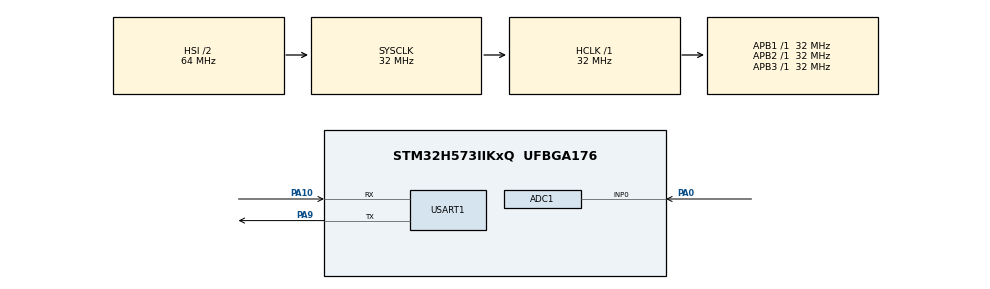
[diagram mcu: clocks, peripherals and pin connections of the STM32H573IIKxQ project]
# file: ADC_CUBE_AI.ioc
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ADC1.Channel-0\#ChannelRegularConversion=ADC_CHANNEL_0
ADC1.MonitoredBy-0\#ChannelRegularConversion=__NULL
ADC1.NbrOfConversionFlag=1
ADC1.OffsetNumber-0\#ChannelRegularConversion=ADC_OFFSET_NONE
ADC1.Rank-0\#ChannelRegularConversion=1
ADC1.SamplingTime-0\#ChannelRegularConversion=ADC_SAMPLETIME_2CYCLES_5
ADC1.master=1
BOOTPATH.BootPathName=LEGACY
BOOTPATH.UserSelectedBootPath=LEGACY
CORTEX_M33_NS.userName=CORTEX_M33
Mcu.Family=STM32H5
Mcu.Name=STM32H573IIKxQ
Mcu.Package=UFBGA176
NVIC.PriorityGroup=NVIC_PRIORITYGROUP_4
PA0.Signal=ADCx_INP0
PA10.Mode=Asynchronous
PA10.Signal=USART1_RX
PA9.Mode=Asynchronous
PA9.Signal=USART1_TX
PH0-OSC_IN(PH0).Mode=HSE-DIG-External-Clock-Source
PH0-OSC_IN(PH0).Signal=RCC_OSC_IN
ProjectManager.HeapSize=0x800
ProjectManager.StackSize=0x800
ProjectManager.TargetToolchain=STM32CubeIDE
RCC.ADCFreq_Value=32000000
RCC.AHBFreq_Value=32000000
RCC.APB1Freq_Value=32000000
RCC.APB1TimFreq_Value=32000000
RCC.APB2Freq_Value=32000000
RCC.APB2TimFreq_Value=32000000
RCC.APB3Freq_Value=32000000
RCC.CSI_VALUE=4000000
RCC.CortexFreq_Value=32000000
RCC.EPOD_VALUE=4000000
RCC.HCLKFreq_Value=32000000
RCC.HSE_VALUE=8000000
RCC.HSI48_VALUE=48000000
RCC.HSI_VALUE=64000000
RCC.LSE_VALUE=32768
RCC.LSIRC_VALUE=32000
RCC.SYSCLKFreq_VALUE=32000000
RCC.USBFreq_Value=48000000
RCC.VCOOutputFreq_Value=516000000
SH.ADCx_INP0.0=ADC1_INP0,IN0-Single-Ended
STMicroelectronics.X-CUBE-AI.10.2.0.ActivationBufferSizeList=5076
STMicroelectronics.X-CUBE-AI.10.2.0.ActivationBuffers=pool0
STMicroelectronics.X-CUBE-AI.10.2.0.ActivationNames=pool0
STMicroelectronics.X-CUBE-AI.10.2.0.ActivationSizes=AI_NETWORK_DATA_ACTIVATION_1_SIZE
STMicroelectronics.X-CUBE-AI.10.2.0.HeapSize=0x800
STMicroelectronics.X-CUBE-AI.10.2.0.InternalRamActivationBufferMaxSize=AI_NETWORK_DATA_ACTIVATIONS_SIZE
STMicroelectronics.X-CUBE-AI.10.2.0.LatestDirectoryUsed-21bf64f0090f801f22865759e371077124c9f304c51981a6d2dc7ec7dad26264=C\:\\Users\\aiXtrusion\\Downloads
STMicroelectronics.X-CUBE-AI.10.2.0.MaximumNumberOfInputLayer=1
STMicroelectronics.X-CUBE-AI.10.2.0.MaximumNumberOfOutputLayer=1
STMicroelectronics.X-CUBE-AI.10.2.0.MaximumSizeOfInputLayer=1
STMicroelectronics.X-CUBE-AI.10.2.0.MaximumSizeOfOutputLayer=1
STMicroelectronics.X-CUBE-AI.10.2.0.ModelActualCompression-21bf64f0090f801f22865759e371077124c9f304c51981a6d2dc7ec7dad26264=0.0
STMicroelectronics.X-CUBE-AI.10.2.0.ModelCompression-21bf64f0090f801f22865759e371077124c9f304c51981a6d2dc7ec7dad26264=None
STMicroelectronics.X-CUBE-AI.10.2.0.ModelFlashOccupation-21bf64f0090f801f22865759e371077124c9f304c51981a6d2dc7ec7dad26264=24200
STMicroelectronics.X-CUBE-AI.10.2.0.ModelHashList=21bf64f0090f801f22865759e371077124c9f304c51981a6d2dc7ec7dad26264
STMicroelectronics.X-CUBE-AI.10.2.0.ModelKind-21bf64f0090f801f22865759e371077124c9f304c51981a6d2dc7ec7dad26264=KERAS
STMicroelectronics.X-CUBE-AI.10.2.0.ModelMacc-21bf64f0090f801f22865759e371077124c9f304c51981a6d2dc7ec7dad26264=34954
STMicroelectronics.X-CUBE-AI.10.2.0.ModelName-21bf64f0090f801f22865759e371077124c9f304c51981a6d2dc7ec7dad26264=network
STMicroelectronics.X-CUBE-AI.10.2.0.ModelNameList=network
STMicroelectronics.X-CUBE-AI.10.2.0.ModelRamOccupation-21bf64f0090f801f22865759e371077124c9f304c51981a6d2dc7ec7dad26264=5076
STMicroelectronics.X-CUBE-AI.10.2.0.ModelStructureFile-21bf64f0090f801f22865759e371077124c9f304c51981a6d2dc7ec7dad26264=C\:\\Users\\aiXtrusion\\Downloads\\pot_model.tflite
STMicroelectronics.X-CUBE-AI.10.2.0.ModelType-21bf64f0090f801f22865759e371077124c9f304c51981a6d2dc7ec7dad26264=STM32Cube.AI MCU runtime
STMicroelectronics.X-CUBE-AI.10.2.0.ReadyForCodeGeneration=true
STMicroelectronics.X-CUBE-AI.10.2.0.StackSize=0x800
STMicroelectronics.X-CUBE-AI.10.2.0.WorkingBufferStartAddrList=0xFFFFFFFF
STMicroelectronics.X-CUBE-AI.10.2.0.XAaCUBEAaAICcArtificialOoIntelligenceJjCore=true
STMicroelectronics.X-CUBE-AI.10.2.0.copyWeightToRam=false
STMicroelectronics.X-CUBE-AI.10.2.0.copyWeightToRam-21bf64f0090f801f22865759e371077124c9f304c51981a6d2dc7ec7dad26264=false
STMicroelectronics.X-CUBE-AI.10.2.0.customLayerConfigEnabled=false
STMicroelectronics.X-CUBE-AI.10.2.0.customLayerConfigEnabled-21bf64f0090f801f22865759e371077124c9f304c51981a6d2dc7ec7dad26264=false
STMicroelectronics.X-CUBE-AI.10.2.0.noOnnxIoTranspose=false
STMicroelectronics.X-CUBE-AI.10.2.0.noOnnxIoTranspose-21bf64f0090f801f22865759e371077124c9f304c51981a6d2dc7ec7dad26264=false
STMicroelectronics.X-CUBE-AI.10.2.0.useInputAllocation=true
STMicroelectronics.X-CUBE-AI.10.2.0.useInputAllocation-21bf64f0090f801f22865759e371077124c9f304c51981a6d2dc7ec7dad26264=true
STMicroelectronics.X-CUBE-AI.10.2.0.useOutputAllocation=true
STMicroelectronics.X-CUBE-AI.10.2.0.useOutputAllocation-21bf64f0090f801f22865759e371077124c9f304c51981a6d2dc7ec7dad26264=true
USART1.VirtualMode-Asynchronous=VM_ASYNC
VP_BOOTPATH_VS_BOOTPATH.Mode=BP_Activate
VP_CORTEX_M33_NS_VS_Hclk.Mode=Hclk_Mode
VP_ICACHE_VS_ICACHE.Mode=DirectMappedCache
VP_MEMORYMAP_VS_MEMORYMAP.Mode=CurAppReg
VP_PWR_VS_LPOM.Mode=PowerOptimisation
VP_PWR_VS_SECSignals.Mode=Security/Privilege
VP_STMicroelectronics.X-CUBE-AI_VS_ArtificialOoIntelligenceJjXAaCUBEAaAI_10.2.0.Mode=ArtificialOoIntelligenceJjXAaCUBEAaAI
board=custom

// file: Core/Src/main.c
/* USER CODE BEGIN Header */
/**
  ******************************************************************************
  * @file           : main.c
  * @brief          : Main program body
  ******************************************************************************
  * @attention
  *
  * Copyright (c) 2025 STMicroelectronics.
  * All rights reserved.
  *
  * This software is licensed under terms that can be found in the LICENSE file
  * in the root directory of this software component.
  * If no LICENSE file comes with this software, it is provided AS-IS.
  *
  ******************************************************************************
  */
/* USER CODE END Header */
#include "main.h"

/* USER CODE BEGIN Includes */
#include "stdio.h"
#include "network.h"
#include "network_data.h"

/* USER CODE END Includes */

ADC_HandleTypeDef hadc1;

UART_HandleTypeDef huart1;

/* USER CODE BEGIN PV */
AI_ALIGNED(4)
static uint8_t activations[AI_NETWORK_DATA_ACTIVATIONS_SIZE];

ai_handle network = AI_HANDLE_NULL;
ai_buffer *ai_input = NULL;
ai_buffer *ai_output = NULL;

volatile int8_t out;
/* USER CODE END PV */

void SystemClock_Config(void);
static void MX_GPIO_Init(void);
static void MX_ADC1_Init(void);
static void MX_ICACHE_Init(void);
static void MX_USART1_UART_Init(void);

/* USER CODE BEGIN 0 */
int _write(int file, char *ptr, int len)
{
    HAL_UART_Transmit(&huart1, (uint8_t*)ptr, len, HAL_MAX_DELAY);
    return len;
}

/* USER CODE END 0 */

int main(void)
{

  /* MCU Configuration--------------------------------------------------------*/

  /* Reset of all peripherals, Initializes the Flash interface and the Systick. */
  HAL_Init();

  /* Configure the system clock */
  SystemClock_Config();

  /* Initialize all configured peripherals */
  MX_GPIO_Init();
  MX_ADC1_Init();
  MX_ICACHE_Init();
  MX_USART1_UART_Init();
  /* USER CODE BEGIN 2 */
  ai_error err;

  /* Create network */
  err = ai_network_create(&network, AI_NETWORK_DATA_CONFIG);
  if (err.type != AI_ERROR_NONE) {
      Error_Handler();
  }

  /* Correct params initialization for X-CUBE-AI 10.x */
  const ai_network_params params = AI_NETWORK_PARAMS_INIT(
      AI_NETWORK_DATA_WEIGHTS(ai_network_data_weights_get()),
      AI_NETWORK_DATA_ACTIVATIONS(activations)
  );

  /* Init network */
  if (!ai_network_init(network, &params)) {
      err = ai_network_get_error(network);
      Error_Handler();
  }

  /* Get input/output buffers */
  ai_input  = ai_network_inputs_get(network, NULL);
  ai_output = ai_network_outputs_get(network, NULL);
  /* USER CODE END 2 */

  /* Infinite loop */
  /* USER CODE BEGIN WHILE */
  while (1)
  {
	  HAL_ADC_Start(&hadc1);
	  	          HAL_ADC_PollForConversion(&hadc1, 10);

	  	          uint32_t adc_val = HAL_ADC_GetValue(&hadc1);

	  	          // Convert ADC to voltage
	  	          float voltage = (float)adc_val * 3.3f / 4095.0f;
	  	          printf("adc_val:   %lu, Vol:  %f	\r",adc_val,voltage);

	  	        int8_t *in = (int8_t *)ai_input[0].data;
	  	      /* Example: fill input with ADC signal */
	  	      int16_t adc = adc_val;  // 0–4095

	  	      /* Normalize to -128..127 (TEMPORARY TEST) */
	  	      int8_t q = (int8_t)((adc - 2048) / 16);

	  	      for (int i = 0; i < AI_NETWORK_IN_1_SIZE; i++) {
	  	          in[i] = q;
	  	      }

	  	        ai_network_run(network, ai_input, ai_output);

	  	         out = ((int8_t *)ai_output[0].data)[0];

	  	        if (out > 0)
	  	            printf("ABNORMAL\r\n");
	  	        else
	  	            printf("NORMAL\r\n");
	  	        HAL_Delay(300);

    /* USER CODE END WHILE */

  }
}

void SystemClock_Config(void)
{
  RCC_OscInitTypeDef RCC_OscInitStruct = {0};
  RCC_ClkInitTypeDef RCC_ClkInitStruct = {0};

  /** Configure the main internal regulator output voltage
  */
  __HAL_PWR_VOLTAGESCALING_CONFIG(PWR_REGULATOR_VOLTAGE_SCALE3);

  while(!__HAL_PWR_GET_FLAG(PWR_FLAG_VOSRDY)) {}

  /** Initializes the RCC Oscillators according to the specified parameters
  * in the RCC_OscInitTypeDef structure.
  */
  RCC_OscInitStruct.OscillatorType = RCC_OSCILLATORTYPE_HSI;
  RCC_OscInitStruct.HSIState = RCC_HSI_ON;
  RCC_OscInitStruct.HSIDiv = RCC_HSI_DIV2;
  RCC_OscInitStruct.HSICalibrationValue = RCC_HSICALIBRATION_DEFAULT;
  RCC_OscInitStruct.PLL.PLLState = RCC_PLL_NONE;
  if (HAL_RCC_OscConfig(&RCC_OscInitStruct) != HAL_OK)
  {
    Error_Handler();
  }

  /** Initializes the CPU, AHB and APB buses clocks
  */
  RCC_ClkInitStruct.ClockType = RCC_CLOCKTYPE_HCLK|RCC_CLOCKTYPE_SYSCLK
                              |RCC_CLOCKTYPE_PCLK1|RCC_CLOCKTYPE_PCLK2
                              |RCC_CLOCKTYPE_PCLK3;
  RCC_ClkInitStruct.SYSCLKSource = RCC_SYSCLKSOURCE_HSI;
  RCC_ClkInitStruct.AHBCLKDivider = RCC_SYSCLK_DIV1;
  RCC_ClkInitStruct.APB1CLKDivider = RCC_HCLK_DIV1;
  RCC_ClkInitStruct.APB2CLKDivider = RCC_HCLK_DIV1;
  RCC_ClkInitStruct.APB3CLKDivider = RCC_HCLK_DIV1;

  if (HAL_RCC_ClockConfig(&RCC_ClkInitStruct, FLASH_LATENCY_1) != HAL_OK)
  {
    Error_Handler();
  }

  /** Configure the programming delay
  */
  __HAL_FLASH_SET_PROGRAM_DELAY(FLASH_PROGRAMMING_DELAY_0);
}

static void MX_ADC1_Init(void)
{

  ADC_ChannelConfTypeDef sConfig = {0};

  /** Common config
  */
  hadc1.Instance = ADC1;
  hadc1.Init.ClockPrescaler = ADC_CLOCK_ASYNC_DIV1;
  hadc1.Init.Resolution = ADC_RESOLUTION_12B;
  hadc1.Init.DataAlign = ADC_DATAALIGN_RIGHT;
  hadc1.Init.ScanConvMode = ADC_SCAN_DISABLE;
  hadc1.Init.EOCSelection = ADC_EOC_SINGLE_CONV;
  hadc1.Init.LowPowerAutoWait = DISABLE;
  hadc1.Init.ContinuousConvMode = DISABLE;
  hadc1.Init.NbrOfConversion = 1;
  hadc1.Init.DiscontinuousConvMode = DISABLE;
  hadc1.Init.ExternalTrigConv = ADC_SOFTWARE_START;
  hadc1.Init.ExternalTrigConvEdge = ADC_EXTERNALTRIGCONVEDGE_NONE;
  hadc1.Init.DMAContinuousRequests = DISABLE;
  hadc1.Init.SamplingMode = ADC_SAMPLING_MODE_NORMAL;
  hadc1.Init.Overrun = ADC_OVR_DATA_PRESERVED;
  hadc1.Init.OversamplingMode = DISABLE;
  if (HAL_ADC_Init(&hadc1) != HAL_OK)
  {
    Error_Handler();
  }

  /** Configure Regular Channel
  */
  sConfig.Channel = ADC_CHANNEL_0;
  sConfig.Rank = ADC_REGULAR_RANK_1;
  sConfig.SamplingTime = ADC_SAMPLETIME_2CYCLES_5;
  sConfig.SingleDiff = ADC_SINGLE_ENDED;
  sConfig.OffsetNumber = ADC_OFFSET_NONE;
  sConfig.Offset = 0;
  if (HAL_ADC_ConfigChannel(&hadc1, &sConfig) != HAL_OK)
  {
    Error_Handler();
  }

}

static void MX_ICACHE_Init(void)
{

  /** Enable instruction cache in 1-way (direct mapped cache)
  */
  if (HAL_ICACHE_ConfigAssociativityMode(ICACHE_1WAY) != HAL_OK)
  {
    Error_Handler();
  }
  if (HAL_ICACHE_Enable() != HAL_OK)
  {
    Error_Handler();
  }

}

static void MX_USART1_UART_Init(void)
{

  huart1.Instance = USART1;
  huart1.Init.BaudRate = 115200;
  huart1.Init.WordLength = UART_WORDLENGTH_8B;
  huart1.Init.StopBits = UART_STOPBITS_1;
  huart1.Init.Parity = UART_PARITY_NONE;
  huart1.Init.Mode = UART_MODE_TX_RX;
  huart1.Init.HwFlowCtl = UART_HWCONTROL_NONE;
  huart1.Init.OverSampling = UART_OVERSAMPLING_16;
  huart1.Init.OneBitSampling = UART_ONE_BIT_SAMPLE_DISABLE;
  huart1.Init.ClockPrescaler = UART_PRESCALER_DIV1;
  huart1.AdvancedInit.AdvFeatureInit = UART_ADVFEATURE_NO_INIT;
  if (HAL_UART_Init(&huart1) != HAL_OK)
  {
    Error_Handler();
  }
  if (HAL_UARTEx_SetTxFifoThreshold(&huart1, UART_TXFIFO_THRESHOLD_1_8) != HAL_OK)
  {
    Error_Handler();
  }
  if (HAL_UARTEx_SetRxFifoThreshold(&huart1, UART_RXFIFO_THRESHOLD_1_8) != HAL_OK)
  {
    Error_Handler();
  }
  if (HAL_UARTEx_DisableFifoMode(&huart1) != HAL_OK)
  {
    Error_Handler();
  }

}

static void MX_GPIO_Init(void)
{

  /* GPIO Ports Clock Enable */
  __HAL_RCC_GPIOA_CLK_ENABLE();
  __HAL_RCC_GPIOH_CLK_ENABLE();

}

void Error_Handler(void)
{
  __disable_irq();
  while (1)
  {
  }
}
